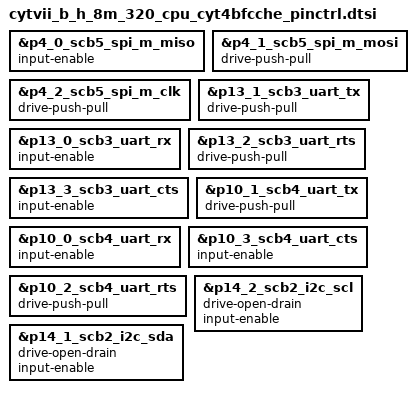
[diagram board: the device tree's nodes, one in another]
/*
 * Copyright (c) 2025 Infineon Technologies AG,
 * or an affiliate of Infineon Technologies AG.
 * Copyright (c) 2026 Linumiz
 * SPDX-License-Identifier: Apache-2.0
 */

/* Configure pin control bias mode for spi pins */
&p4_0_scb5_spi_m_miso {
	input-enable;
};

&p4_1_scb5_spi_m_mosi {
	drive-push-pull;
};

&p4_2_scb5_spi_m_clk {
	drive-push-pull;
};

/* Configure pin control bias mode for uart pins */
&p13_1_scb3_uart_tx {
	drive-push-pull;
};

&p13_0_scb3_uart_rx {
	input-enable;
};

&p13_2_scb3_uart_rts {
	drive-push-pull;
};

&p13_3_scb3_uart_cts {
	input-enable;
};

&p10_1_scb4_uart_tx {
	drive-push-pull;
};

&p10_0_scb4_uart_rx {
	input-enable;
};

&p10_3_scb4_uart_cts {
	input-enable;
};

&p10_2_scb4_uart_rts {
	drive-push-pull;
};

&p14_2_scb2_i2c_scl {
	drive-open-drain;
	input-enable;
};

&p14_1_scb2_i2c_sda {
	drive-open-drain;
	input-enable;
};
